# STM32U5F7 register map
File version: 1.1
CPU: CM33 r0p1, little endian, MPU, FPU, 4 interrupt priority bits
Registers are 32-bit, read-write, reset 0x0 unless marked. A register's access mark holds for its fields unless they carry their own. Offsets are from the block's base; [hi:lo] are bit positions; 'fields as' and 'values as' point back to an identical list.

## LTDC
Base 0x40016800
Same registers: SEC_LTDC 0x50016800
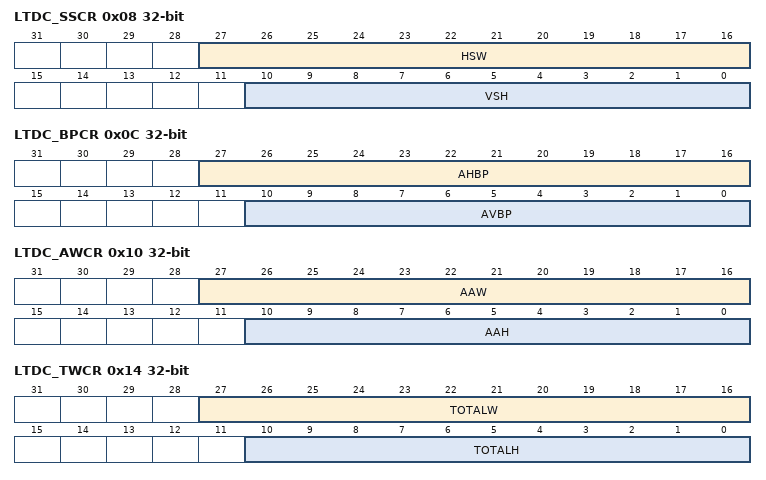
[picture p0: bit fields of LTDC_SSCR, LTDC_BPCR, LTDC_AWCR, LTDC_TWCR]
0x08 LTDC_SSCR — LTDC synchronization size configuration register
  [27:16] HSW — horizontal synchronization width (in units of pixel clock period)
  [10:0] VSH — vertical synchronization height (in units of horizontal scan line)
0x0C LTDC_BPCR — LTDC back porch configuration register
  [27:16] AHBP — accumulated horizontal back porch (in units of pixel clock period)
  [10:0] AVBP — accumulated Vertical back porch (in units of horizontal scan line)
0x10 LTDC_AWCR — LTDC active width configuration register
  [27:16] AAW — accumulated active width (in units of pixel clock period)
  [10:0] AAH — accumulated active height (in units of horizontal scan line)
0x14 LTDC_TWCR — LTDC total width configuration register
  [27:16] TOTALW — total width (in units of pixel clock period)
  [10:0] TOTALH — total height (in units of horizontal scan line)
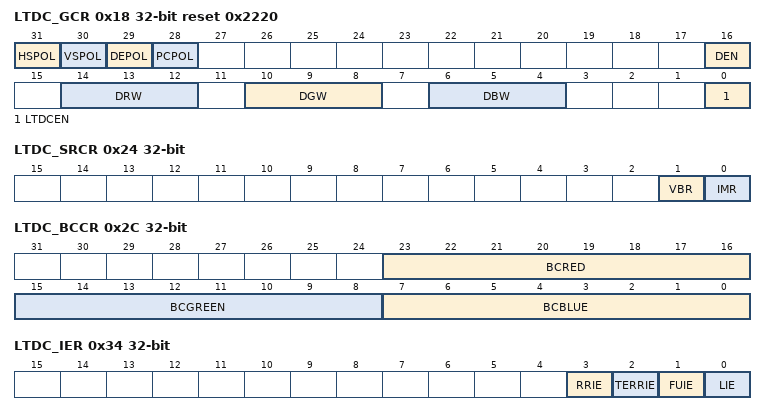
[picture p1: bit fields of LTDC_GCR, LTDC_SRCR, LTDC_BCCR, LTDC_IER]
0x18 LTDC_GCR access per field reset 0x2220 — LTDC global control register
  [31] HSPOL rw — horizontal synchronization polarity
    0=horizontal synchronization polarity is active low; 1=horizontal synchronization polarity is active high
  [30] VSPOL rw — vertical synchronization polarity
    0=vertical synchronization is active low; 1=vertical synchronization is active high
  [29] DEPOL rw — not data enable polarity
    0=not data enable polarity is active low; 1=not data enable polarity is active high
  [28] PCPOL rw — pixel clock polarity
    0=pixel clock polarity is active low; 1=pixel clock is active high
  [16] DEN rw — dither enable
    0=dither disabled; 1=dither enabled
  [14:12] DRW ro — dither red width
  [10:8] DGW ro — dither green width
  [6:4] DBW ro — dither blue width
  [0] LTDCEN rw — LCD-TFT controller enable
    0=LTDC disabled; 1=LTDC enabled
0x24 LTDC_SRCR — LTDC shadow reload configuration register
  [1] VBR — vertical blanking reload
    0=no effect; 1=The shadow registers are reloaded during the vertical blanking period (at the beginning of the first line after the active display area)
  [0] IMR — immediate reload
    0=no effect; 1=The shadow registers are reloaded immediately
0x2C LTDC_BCCR — LTDC background color configuration register
  [23:16] BCRED — background color red value
  [15:8] BCGREEN — background color green value
  [7:0] BCBLUE — background color blue value
0x34 LTDC_IER — LTDC interrupt enable register
  [3] RRIE — register reload interrupt enable
    0=register reload interrupt disable; 1=register reload interrupt enable
  [2] TERRIE — transfer error interrupt enable
    0=transfer error interrupt disable; 1=transfer error interrupt enable
  [1] FUIE — FIFO underrun interrupt enable
    0=FIFO underrun interrupt disable; 1=FIFO underrun Interrupt enable
  [0] LIE — line interrupt enable
    0=line interrupt disable; 1=line interrupt enable
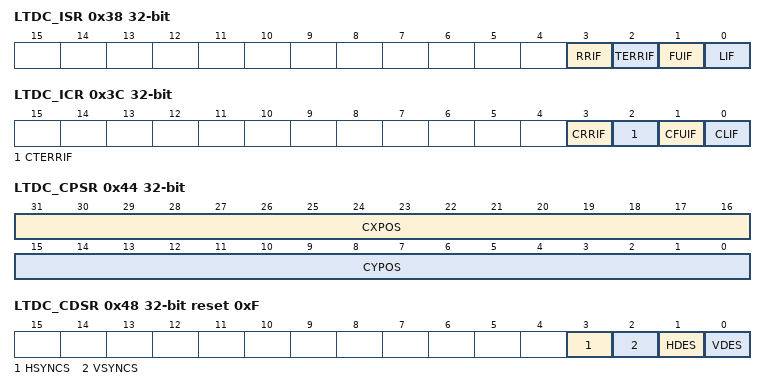
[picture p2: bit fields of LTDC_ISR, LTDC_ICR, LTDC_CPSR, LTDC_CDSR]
0x38 LTDC_ISR ro — LTDC interrupt status register
  [3] RRIF — register reload interrupt flag
    0=no register reload interrupt generated; 1=register reload interrupt generated when a vertical blanking reload occurs (and the first line after the active area is reached)
  [2] TERRIF — transfer error interrupt flag
    0=no transfer error interrupt generated; 1=transfer error interrupt generated when a bus error occurs
  [1] FUIF — FIFO underrun interrupt flag
    0=no FIFO underrun interrupt generated; 1=FIFO underrun interrupt generated, if one of the layer FIFOs is empty and pixel data is read from the FIFO
  [0] LIF — line interrupt flag
    0=no line interrupt generated; 1=line interrupt generated when a programmed line is reached
0x3C LTDC_ICR wo
  [3] CRRIF — clears register reload interrupt flag
    0=no effect; 1=clears the RRIF flag in the LTDC_ISR register
  [2] CTERRIF — clears the transfer error interrupt flag
    0=no effect; 1=clears the TERRIF flag in the LTDC_ISR register
  [1] CFUIF — clears the FIFO underrun interrupt flag
    0=no effect; 1=clears the FUDERRIF flag in the LTDC_ISR register
  [0] CLIF — clears the line interrupt flag
    0=no effect; 1=clears the LIF flag in the LTDC_ISR register
0x40 LTDC_LIPCR — LTDC line interrupt position configuration register
  [10:0] LIPOS — line interrupt position
0x44 LTDC_CPSR ro
  [31:16] CXPOS — current X position
  [15:0] CYPOS — current Y position
0x48 LTDC_CDSR ro reset 0xF — LTDC current display status register
  [all] fields
    0=active low; 1=active high
  [3] HSYNCS — horizontal synchronization display status
  [2] VSYNCS — vertical synchronization display status
  [1] HDES — horizontal data enable display status
  [0] VDES — vertical data enable display status
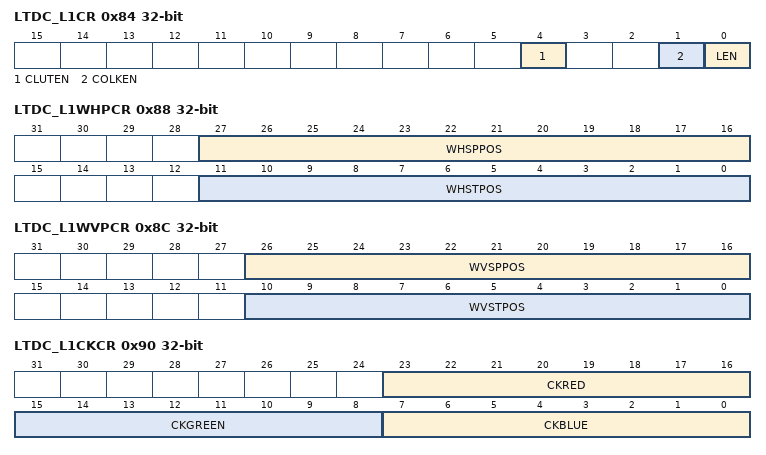
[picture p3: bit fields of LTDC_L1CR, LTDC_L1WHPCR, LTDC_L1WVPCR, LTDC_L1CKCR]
0x84 LTDC_L1CR
  [4] CLUTEN — color look-up table enable
    0=color look-up table disable; 1=color look-up table enable
  [1] COLKEN — color keying enable
    0=color keying disable; 1=color keying enable
  [0] LEN — layer enable
    0=layer disable; 1=layer enable
0x88 LTDC_L1WHPCR — LTDC layer 1 window horizontal position configuration register
  [27:16] WHSPPOS — window horizontal stop position
  [11:0] WHSTPOS — window horizontal start position
0x8C LTDC_L1WVPCR — LTDC layer 1 window vertical position configuration register
  [26:16] WVSPPOS — window vertical stop position
  [10:0] WVSTPOS — window vertical start position
0x90 LTDC_L1CKCR — LTDC layer 1 color keying configuration register
  [23:16] CKRED — color key red value
  [15:8] CKGREEN — color key green value
  [7:0] CKBLUE — color key blue value
0x94 LTDC_L1PFCR — LTDC layer 1 pixel format configuration register
  [2:0] PF — pixel format
    0=ARGB8888; 1=RGB888; 2=RGB565; 3=ARGB1555; 4=ARGB4444; 5=L8 (8-bit luminance); 6=AL44 (4-bit alpha, 4-bit luminance); 7=AL88 (8-bit alpha, 8-bit luminance)
0x98 LTDC_L1CACR reset 0xFF — LTDC layer 1 constant alpha configuration register
  [7:0] CONSTA — constant alpha
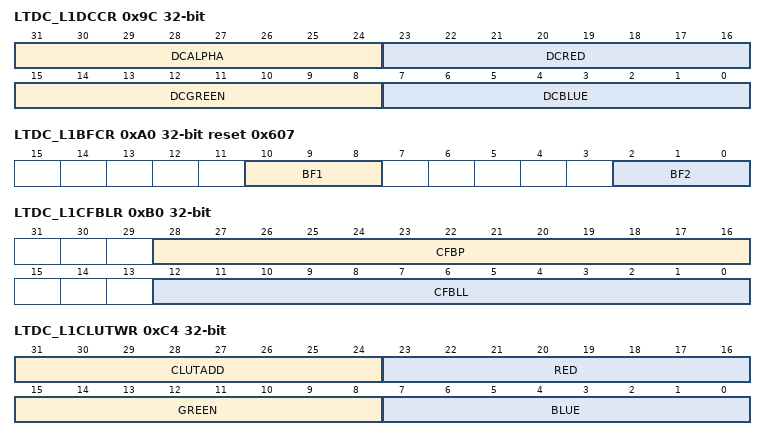
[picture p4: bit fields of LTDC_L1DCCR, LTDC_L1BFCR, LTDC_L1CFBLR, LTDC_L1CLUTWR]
0x9C LTDC_L1DCCR — LTDC layer 1 default color configuration register
  [31:24] DCALPHA — default color alpha
  [23:16] DCRED — default color red
  [15:8] DCGREEN — default color green
  [7:0] DCBLUE — default color blue
0xA0 LTDC_L1BFCR reset 0x607 — LTDC layer 1 blending factors configuration register
  [10:8] BF1 — blending factor 1
    4=constant alpha; 6=pixel alpha x constant alpha
  [2:0] BF2 — blending factor 2
    5=1 - constant alpha; 7=1 - (pixel alpha x constant alpha)
0xAC LTDC_L1CFBAR — LTDC layer 1 color frame buffer address register
  [31:0] CFBADD — color frame buffer start address
0xB0 LTDC_L1CFBLR — LTDC layer 1 color frame buffer length register
  [28:16] CFBP — color frame buffer pitch in bytes
  [12:0] CFBLL — color frame buffer line length
0xB4 LTDC_L1CFBLNR — LTDC layer 1 color frame buffer line number register
  [10:0] CFBLNBR — frame buffer line number
0xC4 LTDC_L1CLUTWR wo — LTDC layer 1 CLUT write register
  [31:24] CLUTADD — CLUT address
  [23:16] RED — red value
  [15:8] GREEN — green value
  [7:0] BLUE — blue value
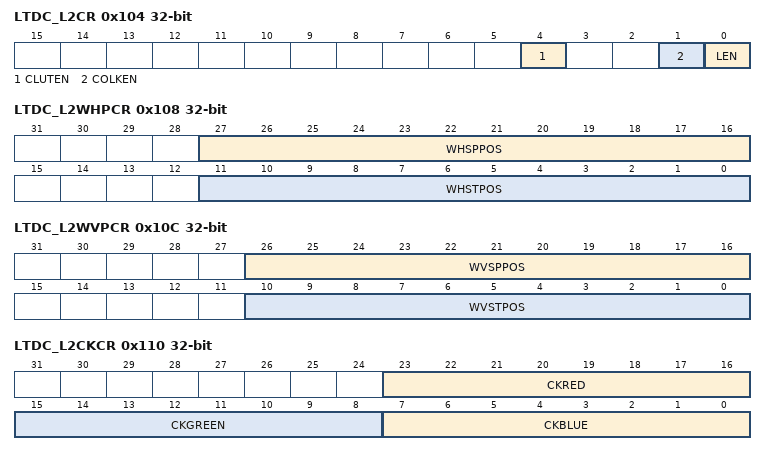
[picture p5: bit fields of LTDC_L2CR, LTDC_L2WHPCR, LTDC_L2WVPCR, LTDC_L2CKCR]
0x104 LTDC_L2CR
  fields as LTDC_L1CR
0x108 LTDC_L2WHPCR — LTDC layer 2 window horizontal position configuration register
  fields as LTDC_L1WHPCR
0x10C LTDC_L2WVPCR — LTDC layer 2 window vertical position configuration register
  fields as LTDC_L1WVPCR
0x110 LTDC_L2CKCR — LTDC layer 2 color keying configuration register
  fields as LTDC_L1CKCR
0x114 LTDC_L2PFCR — LTDC layer 2 pixel format configuration register
  fields as LTDC_L1PFCR
0x118 LTDC_L2CACR reset 0xFF — LTDC layer 2 constant alpha configuration register
  [7:0] CONSTA — constant alpha
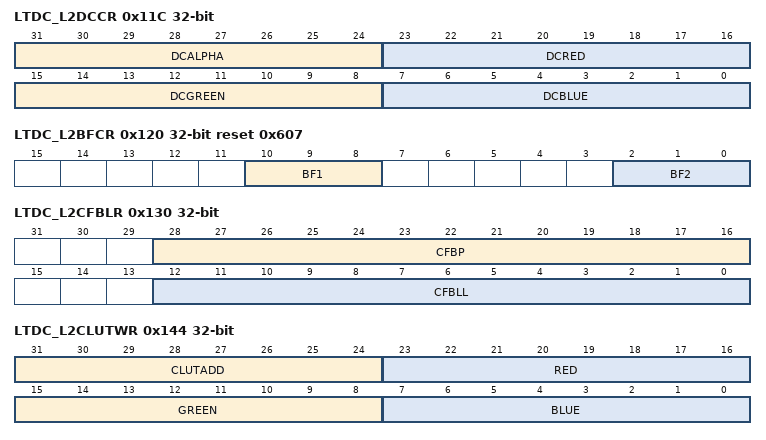
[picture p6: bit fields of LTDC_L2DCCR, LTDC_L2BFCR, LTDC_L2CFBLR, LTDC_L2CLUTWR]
0x11C LTDC_L2DCCR — LTDC layer 2 default color configuration register
  fields as LTDC_L1DCCR
0x120 LTDC_L2BFCR reset 0x607 — LTDC layer 2 blending factors configuration register
  fields as LTDC_L1BFCR
0x12C LTDC_L2CFBAR — LTDC layer 2 color frame buffer address register
  [31:0] CFBADD — color frame buffer start address
0x130 LTDC_L2CFBLR — LTDC layer 2 color frame buffer length register
  fields as LTDC_L1CFBLR
0x134 LTDC_L2CFBLNR — LTDC layer 2 color frame buffer line number register
  [10:0] CFBLNBR — frame buffer line number
0x144 LTDC_L2CLUTWR wo — LTDC layer 2 CLUT write register
  fields as LTDC_L1CLUTWR
